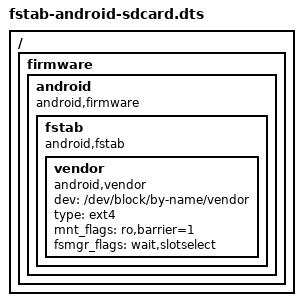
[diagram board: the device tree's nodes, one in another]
/dts-v1/;
/plugin/;

/{
  fragment_root {
    target-path = "/";
    __overlay__ {
	firmware {
	    android {
		compatible = "android,firmware";

		fstab {
			compatible = "android,fstab";

			vendor {
				compatible = "android,vendor";
				dev = "/dev/block/by-name/vendor";
				type = "ext4";
				mnt_flags = "ro,barrier=1";
				fsmgr_flags = "wait,slotselect";
			};
		};
	    };
	};
    };
  };
};
